# LPC11U6x register map
File version: 0.8
CPU: CM0PLUS r0p1, little endian, no MPU, no FPU, 2 interrupt priority bits
Registers are 32-bit, read-write, reset 0x0 unless marked. A register's access mark holds for its fields unless they carry their own. Offsets are from the block's base; [hi:lo] are bit positions; {n}, {i} and the like mark numbered series.

## PINT — Pin interrupt and pattern match (PINT)
Base 0xA0004000
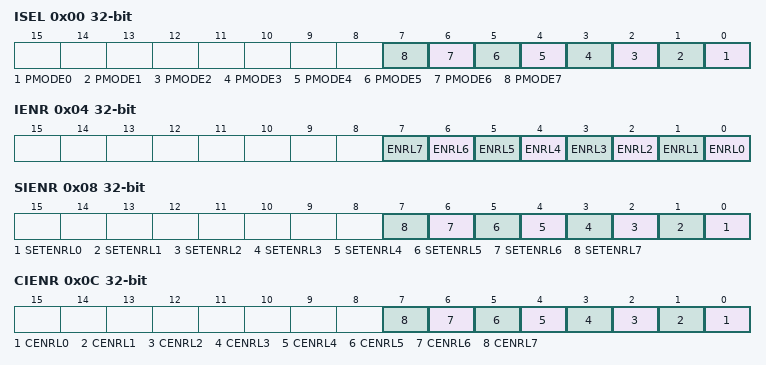
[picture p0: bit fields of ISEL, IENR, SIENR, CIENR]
0x00 ISEL — Pin Interrupt Mode register
  [n] PMODE{n} (n=0..7) — Selects the interrupt mode for each pin interrupt. Bit n configures the pin interrupt selected in PINTSELn. 0 = Edge sensitive 1 = Level sensitive
0x04 IENR — Pin interrupt level or rising edge interrupt enable register
  [n] ENRL{n} (n=0..7) — Enables the rising edge or level interrupt for each pin interrupt. Bit n configures the pin interrupt selected in PINTSELn. 0 = Disable rising edge or level interrupt. 1 = Enable rising edge or level interrupt.
0x08 SIENR wo reset not defined — Pin interrupt level or rising edge interrupt set register
  [n] SETENRL{n} (n=0..7) — Ones written to this address set bits in the IENR, thus enabling interrupts. Bit n sets bit n in the IENR register. 0 = No operation. 1 = Enable rising edge or level interrupt.
0x0C CIENR wo reset not defined — Pin interrupt level (rising edge interrupt) clear register
  [n] CENRL{n} (n=0..7) — Ones written to this address clear bits in the IENR, thus disabling the interrupts. Bit n clears bit n in the IENR register. 0 = No operation. 1 = Disable rising edge or level interrupt.
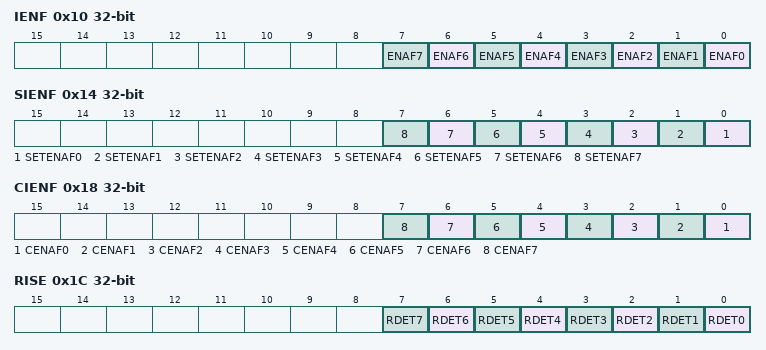
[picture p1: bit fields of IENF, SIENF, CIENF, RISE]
0x10 IENF — Pin interrupt active level or falling edge interrupt enable register
  [n] ENAF{n} (n=0..7) — Enables the falling edge or configures the active level interrupt for each pin interrupt. Bit n configures the pin interrupt selected in PINTSELn. 0 = Disable falling edge interrupt or set active interrupt level LOW. 1 = Enable falling edge interrupt enabled or set active interrupt level HIGH.
0x14 SIENF wo reset not defined — Pin interrupt active level or falling edge interrupt set register
  [n] SETENAF{n} (n=0..7) — Ones written to this address set bits in the IENF, thus enabling interrupts. Bit n sets bit n in the IENF register. 0 = No operation. 1 = Select HIGH-active interrupt or enable falling edge interrupt.
0x18 CIENF wo reset not defined — Pin interrupt active level or falling edge interrupt clear register
  [n] CENAF{n} (n=0..7) — Ones written to this address clears bits in the IENF, thus disabling interrupts. Bit n clears bit n in the IENF register. 0 = No operation. 1 = LOW-active interrupt selected or falling edge interrupt disabled.
0x1C RISE — Pin interrupt rising edge register
  [n] RDET{n} (n=0..7) — Rising edge detect. Bit n detects the rising edge of the pin selected in PINTSELn. Read 0: No rising edge has been detected on this pin since Reset or the last time a one was written to this bit. Write 0: no operation. Read 1: a rising edge has been detected since Reset or the last time a one was written to this bit. Write 1: clear rising edge detection for this pin.
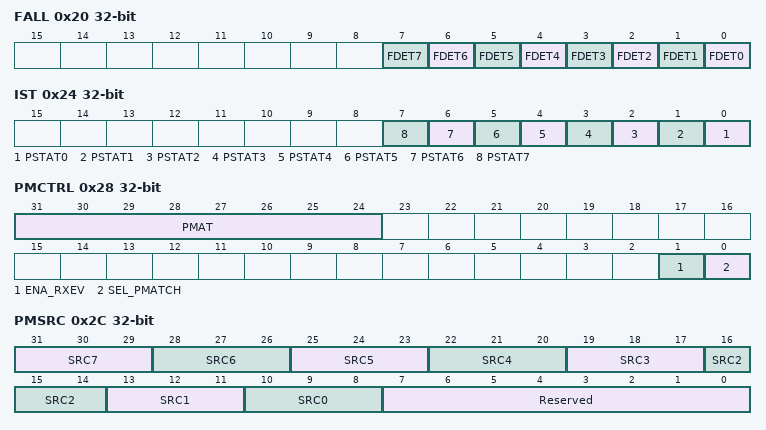
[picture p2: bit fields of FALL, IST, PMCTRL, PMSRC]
0x20 FALL — Pin interrupt falling edge register
  [n] FDET{n} (n=0..7) — Falling edge detect. Bit n detects the falling edge of the pin selected in PINTSELn. Read 0: No falling edge has been detected on this pin since Reset or the last time a one was written to this bit. Write 0: no operation. Read 1: a falling edge has been detected since Reset or the last time a one was written to this bit. Write 1: clear falling edge detection for this pin.
0x24 IST — Pin interrupt status register
  [n] PSTAT{n} (n=0..7) — Pin interrupt status. Bit n returns the status, clears the edge interrupt, or inverts the active level of the pin selected in PINTSELn. Read 0: interrupt is not being requested for this interrupt pin. Write 0: no operation. Read 1: interrupt is being requested for this interrupt pin. Write 1 (edge-sensitive): clear rising- and falling-edge detection for this pin. Write 1 (level-sensitive): switch the active level for this pin (in the IENF register).
0x28 PMCTRL — Pattern match interrupt control register
  [31:24] PMAT — This field displays the current state of pattern matches. A 1 in any bit of this field indicates that the corresponding product term is matched by the current state of the appropriate inputs.
  [1] ENA_RXEV — Enables the RXEV output to the ARM cpu and/or to a GPIO output when the specified boolean expression evaluates to true.
    0=DISABLED_RXEV_OUTPU (Disabled. RXEV output to the cpu is disabled.); 1=ENABLED_RXEV_OUTPUT (Enabled. RXEV output to the cpu is enabled.)
  [0] SEL_PMATCH — Specifies whether the 8 pin interrupts are controlled by the pin interrupt function or by the pattern match function.
    0=PIN_INTERRUPT_INTER (Pin interrupt. Interrupts are driven in response to the standard pin interrupt function); 1=PATTERN_MATCH_INTER (Pattern match. Interrupts are driven in response to pattern matches.)
0x2C PMSRC — Pattern match interrupt bit-slice source register
  [3n+10:3n+8] SRC{n} (n=1..7) — Selects the input source for bit slice {n}
    {v}=INPUT_{v}_SELECTS_PIN (Input {v}. Selects pin interrupt input {v} as the source to bit slice {n}.) (v=0..7)
  [10:8] SRC0 — Selects the input source for bit slice 0
    {v}=INPUT_{v}_SELECTS_PIN (Input {v}. Selects the output of pin interrupt select register {v} as the source to bit slice 0.) (v=0..7)
  [7:0] Reserved — Software should not write 1s to unused bits.
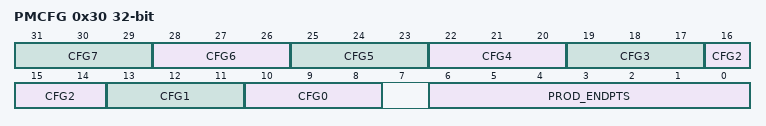
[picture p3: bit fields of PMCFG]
0x30 PMCFG — Pattern match interrupt bit slice configuration register
  [3n+10:3n+8] CFG{n} (n=0..7) — Specifies the match contribution condition for bit slice {n}.
    0=CONSTANT_HIGH_THIS_ (Constant HIGH. This bit slice always contributes to a product term match.); 1=STICKY_RISING_EDGEMA (Sticky rising edgeMatch occurs if a rising edge on the specified input has occurred since the last time the edge detection for this bit slice was cleared. This bit is only cleared when the PMCFG or the PMSRC registers are written to.); 2=STICKY_FALLING_EDGE_ (Sticky falling edge. Match occurs if a falling edge on the specified input has occurred since the last time the edge detection for this bit slice was cleared. This bit is only cleared when the PMCFG or the PMSRC registers are written to.); 3=STICKY_RISING_OR_FAL (Sticky rising or falling edge. Match occurs if either a rising or falling edge on the specified input has occurred since the last time the edge detection for this bit slice was cleared. This bit is only cleared when the PMCFG or the PMSRC registers are written to.); 4=HIGH_LEVEL_MATCH_F (High level. Match (for this bit slice) occurs when there is a high level on the input specified for this bit slice in the PMSRC register.); 5=LOW_LEVEL_MATCH_OCC (Low level. Match occurs when there is a low level on the specified input.); 6=CONSTANT_0_THIS_BIT (Constant 0. This bit slice never contributes to a match (should be used to disable any unused bit slices).); 7=EVENT_NON_STICKY_RI (Event. Non-sticky rising or falling edge. Match occurs on an event - i.e. when either a rising or falling edge is first detected on the specified input (this is a non-sticky version of option 3) . This bit is cleared after one clock cycle.)
  [6:0] PROD_ENDPTS — A 1 in any bit of this field causes the corresponding bit slice to be the final component of a product term in the boolean expression. This has two effects: 1. The interrupt request associated with this bit-slice will be asserted whenever a match to that product term is detected. 2. The next bit slice will start a new, independent product term in the boolean expression (i.e. an OR will be inserted in the boolean expression following the element controlled by this bit slice).
